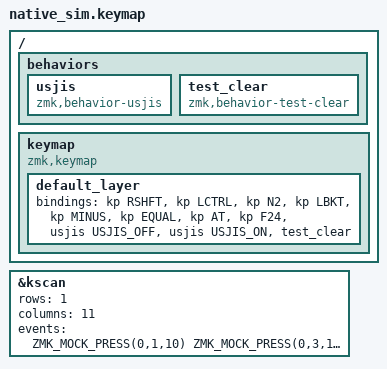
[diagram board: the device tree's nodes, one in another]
/* Generated by tests/zmk/generate.py; do not edit. */
#include <dt-bindings/zmk/keys.h>
#include <behaviors.dtsi>
#include <dt-bindings/zmk/kscan_mock.h>
#include <dt-bindings/zmk/usjis.h>

&kscan {
    rows = <1>;
    columns = <11>;
    events = <
        ZMK_MOCK_PRESS(0,1,10)
        ZMK_MOCK_PRESS(0,3,10)
        ZMK_MOCK_RELEASE(0,3,10)
        ZMK_MOCK_RELEASE(0,1,10)
        ZMK_MOCK_PRESS(0,7,10)
        ZMK_MOCK_RELEASE(0,7,10)
        ZMK_MOCK_PRESS(0,1,10)
        ZMK_MOCK_PRESS(0,0,10)
        ZMK_MOCK_PRESS(0,2,10)
        ZMK_MOCK_RELEASE(0,2,10)
        ZMK_MOCK_RELEASE(0,0,10)
        ZMK_MOCK_RELEASE(0,1,10)
        ZMK_MOCK_PRESS(0,7,10)
        ZMK_MOCK_RELEASE(0,7,10)
        ZMK_MOCK_PRESS(0,6,10)
        ZMK_MOCK_RELEASE(0,6,10)
        ZMK_MOCK_PRESS(0,7,10)
        ZMK_MOCK_RELEASE(0,7,10)
        ZMK_MOCK_PRESS(0,0,10)
        ZMK_MOCK_PRESS(0,4,10)
        ZMK_MOCK_RELEASE(0,0,10)
        ZMK_MOCK_PRESS(0,0,10)
        ZMK_MOCK_RELEASE(0,0,10)
        ZMK_MOCK_RELEASE(0,4,10)
        ZMK_MOCK_PRESS(0,7,10)
        ZMK_MOCK_RELEASE(0,7,10)
        ZMK_MOCK_PRESS(0,5,10)
        ZMK_MOCK_PRESS(0,8,10)
        ZMK_MOCK_RELEASE(0,8,10)
        ZMK_MOCK_PRESS(0,10,10)
        ZMK_MOCK_RELEASE(0,10,10)
        ZMK_MOCK_RELEASE(0,5,10)
        ZMK_MOCK_PRESS(0,5,10)
        ZMK_MOCK_RELEASE(0,5,10)
        ZMK_MOCK_PRESS(0,9,10)
        ZMK_MOCK_RELEASE(0,9,10)
        ZMK_MOCK_PRESS(0,5,10)
        ZMK_MOCK_RELEASE(0,5,10)
    >;
};

/ {
    behaviors {
        usjis: usjis {
            compatible = "zmk,behavior-usjis";
            #binding-cells = <1>;
        };
        test_clear: test_clear {
            compatible = "zmk,behavior-test-clear";
            #binding-cells = <0>;
        };
    };
};

/ {
    keymap {
        compatible = "zmk,keymap";
        default_layer {
            bindings = <
                &kp RSHFT
                &kp LCTRL
                &kp N2
                &kp LBKT
                &kp MINUS
                &kp EQUAL
                &kp AT
                &kp F24
                &usjis USJIS_OFF
                &usjis USJIS_ON
                &test_clear
            >;
        };
    };
};
